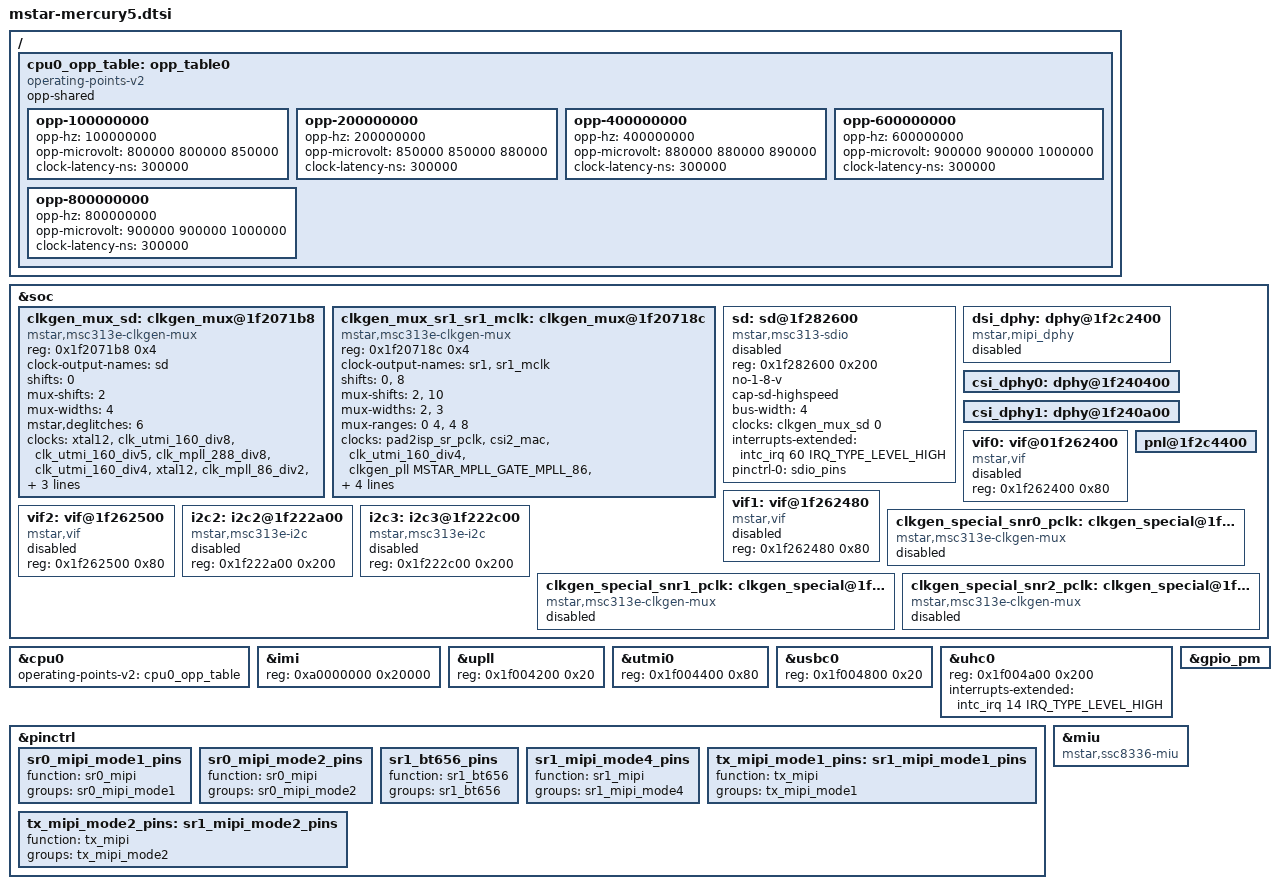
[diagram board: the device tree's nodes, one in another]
// SPDX-License-Identifier: GPL-2.0-or-later
/*
 * Copyright (c) 2020 thingy.jp.
 * Author: Daniel Palmer <daniel@thingy.jp>
 */

#include "mstar-v7.dtsi"

/ {
	cpu0_opp_table: opp_table0 {
		compatible = "operating-points-v2";
		opp-shared;

		opp-100000000 {
			opp-hz = /bits/ 64 <100000000>;
			opp-microvolt = <800000 800000 850000>;
			clock-latency-ns = <300000>;
		};

		opp-200000000 {
			opp-hz = /bits/ 64 <200000000>;
			opp-microvolt = <850000 850000 880000>;
			clock-latency-ns = <300000>;
		};

		opp-400000000 {
			opp-hz = /bits/ 64 <400000000>;
			opp-microvolt = <880000 880000 890000>;
			clock-latency-ns = <300000>;
		};
		opp-600000000 {
			opp-hz = /bits/ 64 <600000000>;
			opp-microvolt = <900000 900000 1000000>;
			clock-latency-ns = <300000>;
		};

		opp-800000000 {
			opp-hz = /bits/ 64 <800000000>;
			opp-microvolt = <900000 900000 1000000>;
			clock-latency-ns = <300000>;
		};
	};
};

&soc {
	/* 
		m5 clkgens
		1f207164 - mipi tx csi

	*/

	clkgen_mux_sd: clkgen_mux@1f2071b8 {
		compatible = "mstar,msc313e-clkgen-mux";
		reg = <0x1f2071b8 0x4>;
		#clock-cells = <1>;
		clock-output-names = "sd";
		shifts = <0>;
		mux-shifts = <2>;
		mux-widths = <4>;
		mstar,deglitches = <6>;
		clocks = <&xtal12>,
			 <&clk_utmi_160_div8>,
			 <&clk_utmi_160_div5>,
			 <&clk_mpll_288_div8>,
			 <&clk_utmi_160_div4>,
			 <&xtal12>,
			 <&clk_mpll_86_div2>,
			 <&xtal12>,
			 <&xtal12>,
			 <&xtal12>,
			 <&xtal12>,
			 <&xtal12>,
			 <&xtal12>,
			 <&xtal12_div40>,
			 <&xtal12>,
			 <&clk_utmi_192_div4>,
			 /* deglitch */
			 <&xtal12>;
	};
	/* guess! */
	clkgen_mux_sr1_sr1_mclk: clkgen_mux@1f20718c {
		compatible = "mstar,msc313e-clkgen-mux";
		reg = <0x1f20718c 0x4>;
		#clock-cells = <1>;
		clock-output-names = "sr1", "sr1_mclk";
		shifts = <0>, <8>;
		mux-shifts = <2>, <10>;
		mux-widths = <2>, <3>;
		mux-ranges = <0 4>, <4 8>;
		clocks =
		/* sr */
		<&pad2isp_sr_pclk>,
		<&csi2_mac>,
		<&clk_utmi_160_div4>,
		<&clkgen_pll MSTAR_MPLL_GATE_MPLL_86>,
		/* sr_mclk */
		<&clk_mpll_216_div8>,
		<&clk_mpll_86_div4>,
		<&xtal12>,
		<&clk_mpll_86_div16>,
		<&clk_mpll_288_div8>,
		<&clk_mpll_216_div4>,
		<&clk_mpll_86_div2>,
		<&clk_mpll_123_div2>;
	};

	sd: sd@1f282600 {
		compatible = "mstar,msc313-sdio";
		reg = <0x1f282600 0x200>;
		no-1-8-v;
		cap-sd-highspeed;
		bus-width = <4>;
		clocks = <&clkgen_mux_sd 0>;
		interrupts-extended = <&intc_irq 60 IRQ_TYPE_LEVEL_HIGH>;
		pinctrl-names = "default";
		pinctrl-0 = <&sdio_pins>;
		status = "disabled";
	};
	
	/*
	clkgen_mux_dsi_tx: clkgen_mux@1f207154 {
	https://github.com/longyanjun2020/SDK_pulbic/blob/c1436fa7446457e8d6547874d27ee4e34be150cf/Mercury5/proj/sc/driver/hal/mercury/mipi_dsi/inc/reg_mipi_dsi.h#L1080
		compatible = "mstar,msc313e-clkgen-mux";
		reg = <0x1f207154 0x4>;
		#clock-cells = <1>;
		clock-output-names = "dsi_tx";
		shifts = <0>;
		mux-shifts = <2>;
		mux-widths = <4>;
		clocks = <&lpll>,
			 <&clkgen_pll MSTAR_MPLL_GATE_UTMI_160>,
			 <&clkgen_pll MSTAR_MPLL_GATE_MPLL_144>,
			 <&clk_mpll_216_div2>,
			 <&clkgen_pll MSTAR_MPLL_GATE_MPLL_216>,
			 <&clkgen_pll MSTAR_MPLL_GATE_UTMI_240>;
	};
	*/

	dsi_dphy: dphy@1f2c2400 {
		//https://github.com/fifteenhex/linux_mstar_3.18/blob/79be86cec45776303b36051bfc0caf5e871975ff/drivers/mstar/driver/hal/infinity2/mipi_dsi/src/halMIPIDsi.c#L201
		compatible = "mstar,mipi_dphy";
		status = "disabled";
	};

	csi_dphy0: dphy@1f240400 {

	};

	csi_dphy1: dphy@1f240a00 {

	};

	vif0: vif@01f262400 {
		compatible = "mstar,vif";
		reg = <0x1f262400 0x80>;
		status = "disabled";
	};

	vif1: vif@1f262480 {
		compatible = "mstar,vif";
		reg = <0x1f262480 0x80>;
		status = "disabled";
	};

	vif2: vif@1f262500 {
		compatible = "mstar,vif";
		reg = <0x1f262500 0x80>;
		status = "disabled";
	};

	pnl@1f2c4400 {
	};

	/*
	dec_misc: dec_misc@1f2c2a00
	*/

	/*
	dsi: dsi@1f344200 {
		
	}
	
	dsi_cmdq: dsi_cmdq@1f344400 {
	
	}


	*/

	i2c2: i2c2@1f222a00 {
		compatible = "mstar,msc313e-i2c";
		reg = <0x1f222a00 0x200>;
		#address-cells = <1>;
		#size-cells = <0>;
		status = "disabled";
	};

	i2c3: i2c3@1f222c00 {
		compatible = "mstar,msc313e-i2c";
		reg = <0x1f222c00 0x200>;
		#address-cells = <1>;
		#size-cells = <0>;
		status = "disabled";
	};

	clkgen_special_snr0_pclk: clkgen_special@1f226708 {
		compatible = "mstar,msc313e-clkgen-mux";
		status = "disabled";
	};

	clkgen_special_snr1_pclk: clkgen_special@1f22670c {
		compatible = "mstar,msc313e-clkgen-mux";
		status = "disabled";
	};

	clkgen_special_snr2_pclk: clkgen_special@1f226710 {
		compatible = "mstar,msc313e-clkgen-mux";
		status = "disabled";
	};
};

&cpu0 {
	operating-points-v2 = <&cpu0_opp_table>;
};

&imi {
	reg = <0xa0000000 0x20000>;
};

&upll {
	reg = <0x1f004200 0x20>;
};

&utmi0 {
	reg = <0x1f004400 0x80>;
};

&usbc0 {
	reg = <0x1f004800 0x20>;
};

&uhc0 {
	reg = <0x1f004a00 0x200>;
	interrupts-extended = <&intc_irq 14 IRQ_TYPE_LEVEL_HIGH>;
};

&gpio_pm {

};

&pinctrl {
	sr0_mipi_mode1_pins: sr0_mipi_mode1_pins {
		function = "sr0_mipi";
		groups = "sr0_mipi_mode1";
	};
	sr0_mipi_mode2_pins: sr0_mipi_mode2_pins {
		function = "sr0_mipi";
		groups = "sr0_mipi_mode2";
	};
	sr1_bt656_pins: sr1_bt656_pins {
		function = "sr1_bt656";
		groups = "sr1_bt656";
	};
	sr1_mipi_mode4_pins: sr1_mipi_mode4_pins {
		function = "sr1_mipi";
		groups = "sr1_mipi_mode4";
	};
	tx_mipi_mode1_pins: sr1_mipi_mode1_pins {
		function = "tx_mipi";
		groups = "tx_mipi_mode1";
	};
	tx_mipi_mode2_pins: sr1_mipi_mode2_pins {
		function = "tx_mipi";
		groups = "tx_mipi_mode2";
	};
};

&miu {
	compatible = "mstar,ssc8336-miu";
};
